# GD32H71x_72x register map
File version: 1.0
CPU: CM7 r1p2, little endian, MPU, FPU, 4 interrupt priority bits
Registers are 32-bit, read-write, reset 0x0 unless marked. A register's access mark holds for its fields unless they carry their own. Offsets are from the block's base; [hi:lo] are bit positions.

## SPI0 — Serial peripheral interface/Inter-IC sound
Base 0x40013000
Same registers: SPI1 0x40003800, SPI2 0x40003C00, SPI5 0x40013800
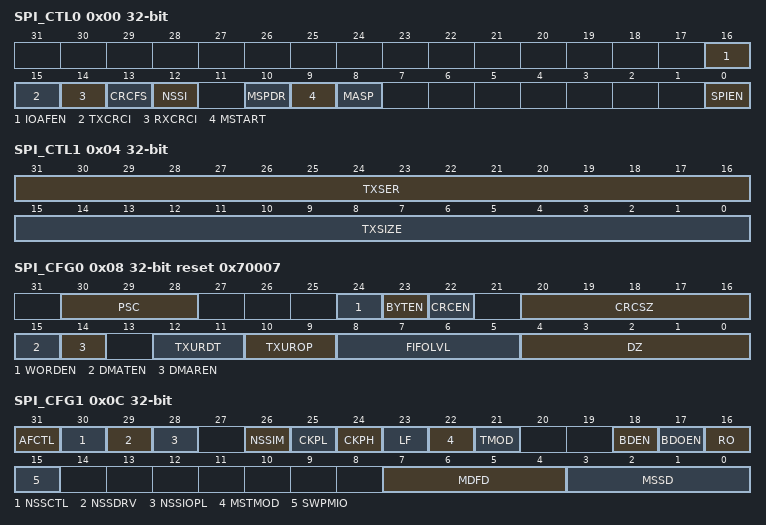
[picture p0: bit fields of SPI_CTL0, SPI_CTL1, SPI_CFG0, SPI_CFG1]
0x00 SPI_CTL0 access per field — Control register 0
  [16] IOAFEN rw — Related IOs AF configuration enable
  [15] TXCRCI rw — The transmitter CRC initialization configuration
  [14] RXCRCI rw — The receiver CRC initialization configuration
  [13] CRCFS rw — Full scale CRC polynomial configuration
  [12] NSSI rw — The input level of internal NSS signal
  [10] MSPDR wo — Suspend request in SPI master mode
  [9] MSTART rw — Master start transfer
  [8] MASP rw — The master is suspended automatically in receive mode
  [0] SPIEN rw — SPI enable
0x04 SPI_CTL1 — Control register 1
  [31:16] TXSER — When previous number of data stored in the TXSIZE has been transferred, it will reload the transmission expansion data amount in the TXSER to TXSIZE.
  [15:0] TXSIZE — The current number of data to transfer
0x08 SPI_CFG0 reset 0x70007 — Configuration register 0
  [30:28] PSC — Master clock prescaler selection
  [24] WORDEN — Word access mode enable
  [23] BYTEN — Byte access mode enable
  [22] CRCEN — CRC calculation enable
  [20:16] CRCSZ — CRC size
  [15] DMATEN — Transmit buffer DMA enable
  [14] DMAREN — Receive buffer DMA enable
  [12:11] TXURDT — Detection of underrun error at slave transmitter
  [10:9] TXUROP — Operation of slave transmitter when underrun detected
  [8:5] FIFOLVL — FIFO threshold level
  [4:0] DZ — Date size
0x0C SPI_CFG1 — Configuration register 1
  [31] AFCTL — AF GPIOs control
  [30] NSSCTL — NSS pin output control in master mode
  [29] NSSDRV — NSS pin output enable in master mode
  [28] NSSIOPL — NSS pin input/output polarity selection
  [26] NSSIM — NSS input signal manage mode
  [25] CKPL — Clock polarity selection
  [24] CKPH — Clock phase selection
  [23] LF — LSB first mode
  [22] MSTMOD — Master mode enable
  [21] TMOD — SPI TI mode enable
  [18] BDEN — Bidirectional enable
  [17] BDOEN — Bidirectional transmit output enable
  [16] RO — Receive only
  [15] SWPMIO — MOSI and MISO pin swap
  [7:4] MDFD — Delay between the data frames in SPI master mode
  [3:0] MSSD — Delay between active edge of NSS and start transfer or receive data in SPI master mode
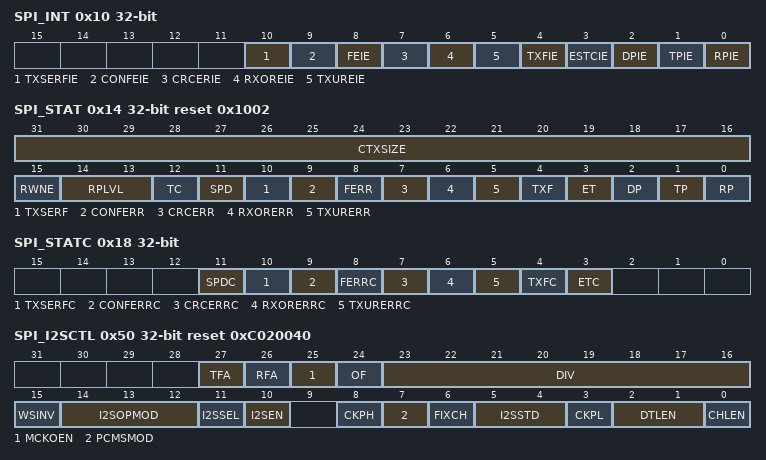
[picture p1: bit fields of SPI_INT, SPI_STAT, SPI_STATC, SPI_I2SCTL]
0x10 SPI_INT — Interrupt register
  [10] TXSERFIE — TXSER reload interrupt enable
  [9] CONFEIE — SPI configuration error interrupt enable
  [8] FEIE — TI frame error interrupt enable
  [7] CRCERIE — CRC error interrupt enable
  [6] RXOREIE — Overrun error interrupt enable
  [5] TXUREIE — Underrun error interrupt enable
  [4] TXFIE — Transmission filled interrupt enable
  [3] ESTCIE — End of transfer or suspend or TxFIFO clear interrupt enable
  [2] DPIE — DP interrupt enable
  [1] TPIE — TP interrupt enable
  [0] RPIE — RP interrupt enable
0x14 SPI_STAT ro reset 0x1002 — Status register
  [31:16] CTXSIZE — These bits show the number of data frames remaining in the TXSIZE bit field (in the SPI_CTL1 register).
  [15] RWNE — The word of RxFIFO is not empty
  [14:13] RPLVL — RxFIFO packet level
  [12] TC — TxFIFO transmission complete flag
  [11] SPD — Suspend flag
  [10] TXSERF — The additional SPI data has been reloaded
  [9] CONFERR — SPI configuration error
  [8] FERR — SPI TI format error
  [7] CRCERR — SPI CRC error
  [6] RXORERR — Reception overrun error
  [5] TXURERR — Transmission underrun error
  [4] TXF — TxFIFO transmission has been filled
  [3] ET — End of transmission / reception flag
  [2] DP — Duplex packet
  [1] TP — TxFIFO packet space available flag
  [0] RP — RxFIFO packet space available flag
0x18 SPI_STATC wo — Interrupt/Status flags clear register
  [11] SPDC — Clear the suspend flag
  [10] TXSERFC — Clear the TXSERF flag
  [9] CONFERRC — Clear the configuration error flag
  [8] FERRC — Clear the SPI TI format error flag
  [7] CRCERRC — Clear the CRC error flag
  [6] RXORERRC — Clear the reception overrun error flag
  [5] TXURERRC — Clear the transmission underrun error flag
  [4] TXFC — Clear the TxFIFO transmission filled flag
  [3] ETC — Clear the end of transmission/reception flag
0x20 SPI_TDATA wo — Data Transfer register
  [31:0] TDATA — Data transfer register
0x30 SPI_RDATA ro — Data Receive register
  [31:0] RDATA — Data receive register
0x40 SPI_CRCPOLY reset 0x107 — CRC polynomial register
0x44 SPI_TCRC ro — TX CRC register
  [31:0] TCRC — Tx CRC register.
0x48 SPI_RCRC ro — RX CRC register
  [31:0] RCRC — Rx CRC register.
0x4C SPI_URDATA — Underrun Data register
  [31:0] URDATA — Transmission underrun data at slave mode.
0x50 SPI_I2SCTL access per field reset 0xC020040 — I2S control register
  [27] TFA ro — TXFIFO available
  [26] RFA ro — RXFIFO available
  [25] MCKOEN rw — I2S_MCK output enable
  [24] OF rw — Odd factor for the prescaler
  [23:16] DIV rw — Dividing factor for the prescaler
  [15] WSINV rw — I2S_WS signal polarity inversion
  [14:12] I2SOPMOD rw — I2S operation mode
  [11] I2SSEL rw — I2S mode selection
  [10] I2SEN rw — I2S enable
  [8] CKPH rw — Clock signal phase selection (effective only in PCM mode)
  [7] PCMSMOD rw — PCM frame synchronization mode
  [6] FIXCH rw — Fixed channel length
  [5:4] I2SSTD rw — I2S standard selection
  [3] CKPL rw — Idle state clock polarity
  [2:1] DTLEN rw — Data length
  [0] CHLEN rw — Channel length
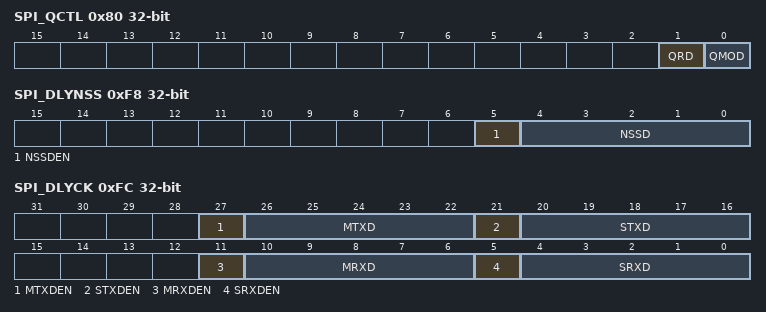
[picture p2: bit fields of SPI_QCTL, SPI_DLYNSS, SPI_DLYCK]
0x80 SPI_QCTL — Quad_SPI mode control register
  [1] QRD — Quad-SPI mode read select
  [0] QMOD — Quad-SPI mode enable
0xF8 SPI_DLYNSS — NSS sampling Clock delay register
  [5] NSSDEN — NSS signal sampling delay enable
  [4:0] NSSD — NSS signal sampling delay units
0xFC SPI_DLYCK — Clock delay register
  [27] MTXDEN — When master transmit, sampling clock delay enable
  [26:22] MTXD — When master transmit, sampling clock delay units
  [21] STXDEN — When slave transmit, sampling clock delay enable
  [20:16] STXD — When slave transmit, sampling clock delay units
  [11] MRXDEN — When master receive, sampling clock delay enable
  [10:6] MRXD — When master receive, sampling clock delay units
  [5] SRXDEN — When slave receive, sampling clock delay enable
  [4:0] SRXD — When slave receive, sampling clock delay units

## SPI3 — Serial peripheral interface/Inter-IC sound
Base 0x40013400
Same registers: SPI6 0x40003400, SPI4 0x40015000, SPI7 0x58001400
Registers as SPI0, without SPI_I2SCTL.
